# CEC1702 register map
Vendor: Microchip
Registers are 32-bit, read-write, reset 0x0 unless marked. A register's access mark holds for its fields unless they carry their own. Addresses are absolute, and some are shared; only a register's first bit layout is shown; [hi:lo] are bit positions; {n}, {i} and the like mark numbered series.

## TACH1
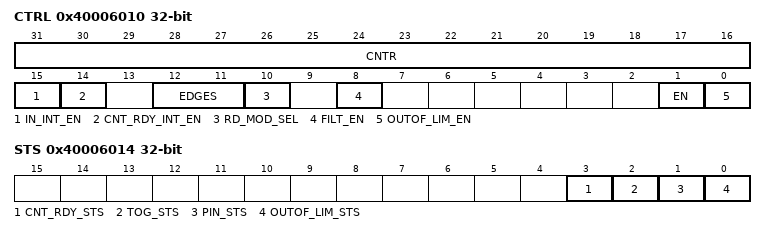
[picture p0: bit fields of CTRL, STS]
0x40006010 CTRL
  [31:16] CNTR — This 16-bit field contains the latched value of the internal Tach pulse counter, which may be configured by the. Tach Reading Mode Select field to operate as a free-running counter or to be gated by the Tach input signal.
  [15] IN_INT_EN — IN_INT_EN 1=Enable Tach Input toggle interrupt from Tach block, 0=Disable Tach Input toggle interrupt from Tach block
  [14] CNT_RDY_INT_EN — CNT_RDY_INT_EN 1=Enable Count Ready interrupt from Tach block, 0=Disable Count Ready interrupt from Tach block
  [12:11] EDGES — EDGES A Tach signal is a square wave with a 50% duty cycle. Typically, two Tach periods represents one revolution of the fan. A Tach period consists of three Tach edges. This programmed value represents the number of Tach edges that will be used to determine the interval for which the number of 100kHz_Clk pulses will be counted. 11b=9 Tach edges (4 Tach periods). 10b=5 Tach edges (2 Tach periods). 01b=3 Tach edges (1 Tach period). 00b=2 Tach edges (1/2 Tach period)
  [10] RD_MOD_SEL — RD_MOD_SEL. 1=Counter is incremented on the rising edge of the 100kHz_Clk input. The counter is latched into the TACHX_COUNTER field and reset when the programmed number of edges is detected. 0=Counter is incremented when Tach Input transitions from low-tohigh state (default)
  [8] FILT_EN — FILT_EN This filter is used to remove high frequency glitches from Tach Input. When this filter is enabled, Tach input pulses less than two 100kHz_- Clk periods wide get filtered. 1= Filter enabled. 0= Filter disabled (default). It is recommended that the Tach input filter always be enabled.
  [1] EN — EN 1= TACH Monitoring enabled, clocks enabled. 0= TACH Idle, clocks gated
  [0] OUTOF_LIM_EN — OUTOF_LIM_EN This bit is used to enable the TACH_OUT_OF_LIMIT_STATUS bit in the TACHx Status Register to generate an interrupt event. 1=Enable interrupt output from Tach block. 0=Disable interrupt output from Tach block (default)
0x40006014 STS
  [3] CNT_RDY_STS — CNT_RDY_STS 1=Reading ready, 0=Reading not ready
  [2] TOG_STS — TOG_STS 1=Tach Input changed state (this bit is set on a low-to-high or high-tolow transition), 0=Tach stable (R/WC)
  [1] PIN_STS — PIN_STS 1= Tach Input is high, 0= Tach Input is low
  [0] OUTOF_LIM_STS — OUTOF_LIM_STS 1=Tach is outside of limits, 0=Tach is within limits (R/WC)
0x40006018 LIM_HI reset 0xFFFF
  [15:0] T_HIGH — This value is compared with the value in the TACHX_COUNTER field. If the value in the counter is greater than the value programmed in this register, the TACH_OUT_OF_LIMIT_STATUS bit will be set. The TACH_OUT_OF_LIMIT_STATUS status event may be enabled to generate an interrupt to the embedded controller via the TACH_OUT_OF_LIMIT_ENABLE bit in the TACHx Control Register.
0x4000601C LIM_LO
  [15:0] T_LOW — This value is compared with the value in the TACHX_COUNTER field of the TACHx Control Register. If the value in the counter is less than the value programmed in this register, the TACH_OUT_OF_LIMIT_STATUS bit will be set. The TACH_OUT_OF_LIMIT_STATUS status event may be enabled to generate an interrupt to the embedded controller via the TACH_OUT_OF_LIMIT_ENABLE bit in the TACHx. Control Register To disable the TACH_OUT_OF_LIMIT_STATUS low event, program 0000h into this register.

## RTOS
0x40007400 CNT
  [31:0] CNTR — This register contains the current value of the RTOS Timer counter. This register should be read as a DWORD. There is no latching mechanism of the upper bytes implemented if the register is accessed as a byte or word. Reading the register with byte or word operations may give incorrect results.
0x40007404 PRLD
  [31:0] PRELOAD — The this register is loaded into the RTOS Timer counter either when the TIMER_START bit is written with a 1, or when the timer counter counts down to 0 and the AUTO_RELOAD bit is 1. This register must be programmed with a new count value before the TIMER_START bit is set to 1. If this register is updated while the counter is operating, the new count value will only take effect if the counter transitions form 1 to 0 while the AUTO_RELOAD bit is set.
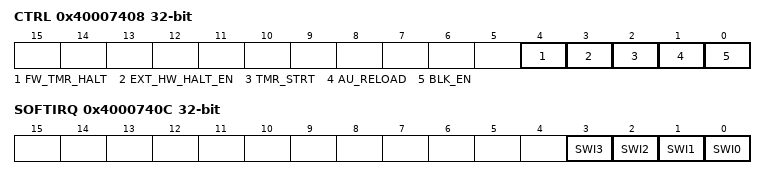
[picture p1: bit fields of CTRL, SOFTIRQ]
0x40007408 CTRL
  [4] FW_TMR_HALT — 1=The timer counter is halted. If the counter was running, clearing this bit will restart the counter from the value at which it halted. 0=The timer counter, if enabled, will continue to run
  [3] EXT_HW_HALT_EN — 1=The timer counter is halted when the external HALT signal is asserted. Counting is always enabled if HALT is de-asserted. 0=The HALT signal does not affect the RTOS Timer
  [2] TMR_STRT — Writing a 1 to this bit will load the timer counter with the RTOS Timer Preload Register and start counting. If the Preload Register is 0, counting will not start and this bit will be cleared to 0. Writing a 0 to this bit will halt the counter and clear its contents to 0. The RTOS timer interrupt will not be generated. This bit is automatically cleared if the AUTO_RELOAD bit is 0 and the timer counter transitions from 1 to 0.
  [1] AU_RELOAD — 1=The the RTOS Timer Preload Register is loaded into the timer counter and the counter is restarted when the counter transitions from 1 to 0. 0=The timer counter halts when it transitions from 1 to 0 and will not restart.
  [0] BLK_EN — 1=RTOS timer counter is enabled. 0=RTOS timer disabled. All register bits are reset to their default state
0x4000740C SOFTIRQ wo
  [n] SWI{n} (n=0..3) — Software Interrupt. A write of a '1' to this bit will generate an SWI interrupt to the EC. Writes of a '0' have no effect. Reads return '0'.
